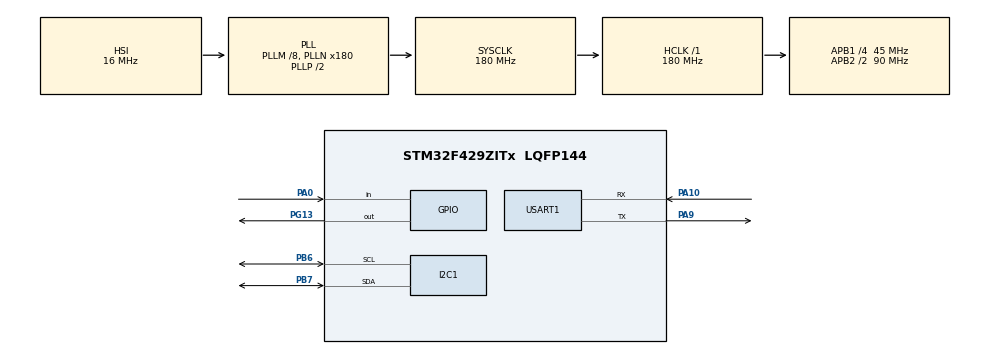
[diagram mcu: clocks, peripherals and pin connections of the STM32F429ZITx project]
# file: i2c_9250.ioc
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Mcu.Family=STM32F4
Mcu.Name=STM32F429ZITx
Mcu.Package=LQFP144
NVIC.PriorityGroup=NVIC_PRIORITYGROUP_4
PA0/WKUP.Signal=GPIO_Input
PA10.Mode=Asynchronous
PA10.Signal=USART1_RX
PA9.Mode=Asynchronous
PA9.Signal=USART1_TX
PB6.Mode=I2C
PB6.Signal=I2C1_SCL
PB7.Mode=I2C
PB7.Signal=I2C1_SDA
PG13.Signal=GPIO_Output
ProjectManager.HeapSize=0x200
ProjectManager.StackSize=0x400
ProjectManager.TargetToolchain=MDK-ARM V5
RCC.48MHZClocksFreq_Value=90000000
RCC.AHBFreq_Value=180000000
RCC.APB1CLKDivider=RCC_HCLK_DIV4
RCC.APB1Freq_Value=45000000
RCC.APB1TimFreq_Value=90000000
RCC.APB2CLKDivider=RCC_HCLK_DIV2
RCC.APB2Freq_Value=90000000
RCC.APB2TimFreq_Value=180000000
RCC.CortexFreq_Value=180000000
RCC.HCLKFreq_Value=180000000
RCC.HSE_VALUE=25000000
RCC.HSI_VALUE=16000000
RCC.LSE_VALUE=32768
RCC.PLLM=8
RCC.PLLN=180
RCC.SYSCLKFreq_VALUE=180000000
RCC.SYSCLKSource=RCC_SYSCLKSOURCE_PLLCLK
RCC.VCOOutputFreq_Value=360000000
USART1.VirtualMode=VM_ASYNC
board=custom

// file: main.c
/* USER CODE BEGIN Header */
/**
  ******************************************************************************
  * @file           : main.c
  * @brief          : Main program body
  ******************************************************************************
  * @attention
  *
  * <h2><center>&copy; Copyright (c) 2019 STMicroelectronics.
  * All rights reserved.</center></h2>
  *
  * This software component is licensed by ST under BSD 3-Clause license,
  * the "License"; You may not use this file except in compliance with the
  * License. You may obtain a copy of the License at:
  *                        opensource.org/licenses/BSD-3-Clause
  *
  ******************************************************************************
  */
/* USER CODE END Header */

#include "main.h"

/* USER CODE BEGIN Includes */
#include "TJ_MPU6050.h"
/* USER CODE END Includes */

I2C_HandleTypeDef hi2c1;

UART_HandleTypeDef huart1;

void SystemClock_Config(void);
static void MX_GPIO_Init(void);
static void MX_I2C1_Init(void);
static void MX_USART1_UART_Init(void);

/* USER CODE BEGIN 0 */
RawData_Def myAccelRaw, myGyroRaw;
ScaledData_Def myAccelScaled, myGyroScaled;
/* USER CODE END 0 */

int main(void)
{
  /* USER CODE BEGIN 1 */
	MPU_ConfigTypeDef mympucomfig;

  /* USER CODE END 1 */

  /* MCU Configuration--------------------------------------------------------*/

  /* Reset of all peripherals, Initializes the Flash interface and the Systick. */
  HAL_Init();

  /* Configure the system clock */
  SystemClock_Config();

  /* Initialize all configured peripherals */
  MX_GPIO_Init();
  MX_I2C1_Init();
  MX_USART1_UART_Init();
  /* USER CODE BEGIN 2 */
 MPU6050_Init(&hi2c1);
mympucomfig.Accel_Full_Scale=AFS_SEL_4g;
mympucomfig.ClockSource=Internal_8MHz;
mympucomfig.CONFIG_DLPF=DLPF_184A_188G_Hz;
mympucomfig.Gyro_Full_Scale=FS_SEL_500;
mympucomfig.Sleep_Mode_Bit=0;
MPU6050_Config(&mympucomfig);
  /* USER CODE END 2 */

  /* Infinite loop */
  while (1)
  {
		//----rawdata
//		MPU6050_Get_Accel_RawData(&myAccelRaw);
//		MPU6050_Get_Gyro_RawData(&myGyroRaw);

//		//----scaleddata
		MPU6050_Get_Accel_Scale(&myAccelScaled);
		MPU6050_Get_Gyro_Scale(&myGyroScaled);

	HAL_GPIO_TogglePin(GPIOG,GPIO_PIN_13);
	HAL_Delay(10);
  }
}

void SystemClock_Config(void)
{
  RCC_OscInitTypeDef RCC_OscInitStruct = {0};
  RCC_ClkInitTypeDef RCC_ClkInitStruct = {0};

  /** Configure the main internal regulator output voltage
  */
  __HAL_RCC_PWR_CLK_ENABLE();
  __HAL_PWR_VOLTAGESCALING_CONFIG(PWR_REGULATOR_VOLTAGE_SCALE1);
  /** Initializes the CPU, AHB and APB busses clocks
  */
  RCC_OscInitStruct.OscillatorType = RCC_OSCILLATORTYPE_HSI;
  RCC_OscInitStruct.HSIState = RCC_HSI_ON;
  RCC_OscInitStruct.HSICalibrationValue = RCC_HSICALIBRATION_DEFAULT;
  RCC_OscInitStruct.PLL.PLLState = RCC_PLL_ON;
  RCC_OscInitStruct.PLL.PLLSource = RCC_PLLSOURCE_HSI;
  RCC_OscInitStruct.PLL.PLLM = 8;
  RCC_OscInitStruct.PLL.PLLN = 180;
  RCC_OscInitStruct.PLL.PLLP = RCC_PLLP_DIV2;
  RCC_OscInitStruct.PLL.PLLQ = 4;
  if (HAL_RCC_OscConfig(&RCC_OscInitStruct) != HAL_OK)
  {
    Error_Handler();
  }
  /** Activate the Over-Drive mode
  */
  if (HAL_PWREx_EnableOverDrive() != HAL_OK)
  {
    Error_Handler();
  }
  /** Initializes the CPU, AHB and APB busses clocks
  */
  RCC_ClkInitStruct.ClockType = RCC_CLOCKTYPE_HCLK|RCC_CLOCKTYPE_SYSCLK
                              |RCC_CLOCKTYPE_PCLK1|RCC_CLOCKTYPE_PCLK2;
  RCC_ClkInitStruct.SYSCLKSource = RCC_SYSCLKSOURCE_PLLCLK;
  RCC_ClkInitStruct.AHBCLKDivider = RCC_SYSCLK_DIV1;
  RCC_ClkInitStruct.APB1CLKDivider = RCC_HCLK_DIV4;
  RCC_ClkInitStruct.APB2CLKDivider = RCC_HCLK_DIV2;

  if (HAL_RCC_ClockConfig(&RCC_ClkInitStruct, FLASH_LATENCY_5) != HAL_OK)
  {
    Error_Handler();
  }
}

static void MX_I2C1_Init(void)
{

  hi2c1.Instance = I2C1;
  hi2c1.Init.ClockSpeed = 100000;
  hi2c1.Init.DutyCycle = I2C_DUTYCYCLE_2;
  hi2c1.Init.OwnAddress1 = 0;
  hi2c1.Init.AddressingMode = I2C_ADDRESSINGMODE_7BIT;
  hi2c1.Init.DualAddressMode = I2C_DUALADDRESS_DISABLE;
  hi2c1.Init.OwnAddress2 = 0;
  hi2c1.Init.GeneralCallMode = I2C_GENERALCALL_DISABLE;
  hi2c1.Init.NoStretchMode = I2C_NOSTRETCH_DISABLE;
  if (HAL_I2C_Init(&hi2c1) != HAL_OK)
  {
    Error_Handler();
  }
  /** Configure Analogue filter
  */
  if (HAL_I2CEx_ConfigAnalogFilter(&hi2c1, I2C_ANALOGFILTER_ENABLE) != HAL_OK)
  {
    Error_Handler();
  }
  /** Configure Digital filter
  */
  if (HAL_I2CEx_ConfigDigitalFilter(&hi2c1, 0) != HAL_OK)
  {
    Error_Handler();
  }

}

static void MX_USART1_UART_Init(void)
{

  huart1.Instance = USART1;
  huart1.Init.BaudRate = 115200;
  huart1.Init.WordLength = UART_WORDLENGTH_8B;
  huart1.Init.StopBits = UART_STOPBITS_1;
  huart1.Init.Parity = UART_PARITY_NONE;
  huart1.Init.Mode = UART_MODE_TX_RX;
  huart1.Init.HwFlowCtl = UART_HWCONTROL_NONE;
  huart1.Init.OverSampling = UART_OVERSAMPLING_16;
  if (HAL_UART_Init(&huart1) != HAL_OK)
  {
    Error_Handler();
  }

}

static void MX_GPIO_Init(void)
{
  GPIO_InitTypeDef GPIO_InitStruct = {0};

  /* GPIO Ports Clock Enable */
  __HAL_RCC_GPIOA_CLK_ENABLE();
  __HAL_RCC_GPIOG_CLK_ENABLE();
  __HAL_RCC_GPIOB_CLK_ENABLE();

  /*Configure GPIO pin Output Level */
  HAL_GPIO_WritePin(GPIOG, GPIO_PIN_13, GPIO_PIN_RESET);

  /*Configure GPIO pin : PA0 */
  GPIO_InitStruct.Pin = GPIO_PIN_0;
  GPIO_InitStruct.Mode = GPIO_MODE_INPUT;
  GPIO_InitStruct.Pull = GPIO_NOPULL;
  HAL_GPIO_Init(GPIOA, &GPIO_InitStruct);

  /*Configure GPIO pin : PG13 */
  GPIO_InitStruct.Pin = GPIO_PIN_13;
  GPIO_InitStruct.Mode = GPIO_MODE_OUTPUT_PP;
  GPIO_InitStruct.Pull = GPIO_NOPULL;
  GPIO_InitStruct.Speed = GPIO_SPEED_FREQ_LOW;
  HAL_GPIO_Init(GPIOG, &GPIO_InitStruct);

}

void Error_Handler(void)
{
}

/************************ (C) COPYRIGHT STMicroelectronics *****END OF FILE****/
